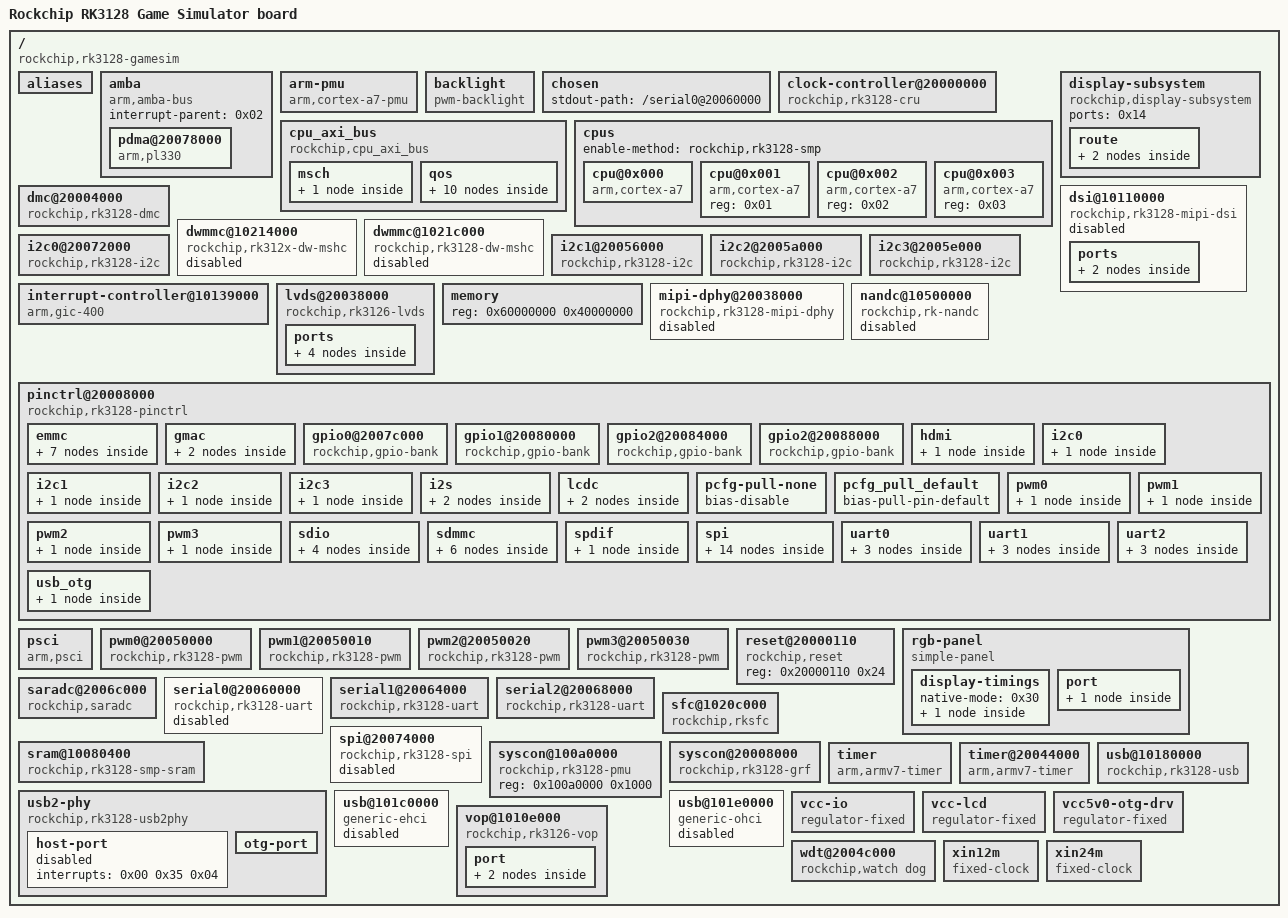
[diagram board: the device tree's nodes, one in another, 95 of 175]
/dts-v1/;

/ {
	#address-cells = <0x01>;
	#size-cells = <0x01>;
	compatible = "rockchip,rk3128-gamesim\0rockchip,rk3128";
	interrupt-parent = <0x02>;
	model = "Rockchip RK3128 Game Simulator board";
	rockchip,sram = <0x01>;

	aliases {
		gpio0 = "/pinctrl@20008000/gpio0@2007c000";
		gpio1 = "/pinctrl@20008000/gpio1@20080000";
		gpio2 = "/pinctrl@20008000/gpio2@20084000";
		gpio3 = "/pinctrl@20008000/gpio2@20088000";
		i2c0 = "/i2c0@20072000";
		i2c1 = "/i2c1@20056000";
		i2c2 = "/i2c2@2005a000";
		i2c3 = "/i2c3@2005e000";
		mmc0 = "/dwmmc@1021c000";
		mmc1 = "/dwmmc@10214000";
		serial0 = "/serial0@20060000";
		serial1 = "/serial1@20064000";
		serial2 = "/serial2@20068000";
		spi0 = "/spi@20074000";
	};

	amba {
		#address-cells = <0x01>;
		#size-cells = <0x01>;
		compatible = "arm,amba-bus";
		interrupt-parent = <0x02>;
		ranges;

		pdma@20078000 {
			#dma-cells = <0x01>;
			arm,pl330-broken-no-flushp;
			clock-names = "apb_pclk";
			clocks = <0x03 0xc2>;
			compatible = "arm,pl330\0arm,primecell";
			interrupts = <0x00 0x00 0x04 0x00 0x01 0x04>;
			phandle = <0x09>;
			reg = <0x20078000 0x4000>;
		};
	};

	arm-pmu {
		compatible = "arm,cortex-a7-pmu";
		interrupts = <0x00 0x4c 0x04 0x00 0x4d 0x04 0x00 0x4e 0x04 0x00 0x4f 0x04>;
	};

	backlight {
		brightness-levels = <0x00 0x01 0x02 0x03 0x04 0x05 0x06 0x07 0x08 0x09 0x0a 0x0b 0x0c 0x0d 0x0e 0x0f 0x10 0x11 0x12 0x13 0x14 0x15 0x16 0x17 0x18 0x19 0x1a 0x1b 0x1c 0x1d 0x1e 0x1f 0x20 0x21 0x22 0x23 0x24 0x25 0x26 0x27 0x28 0x29 0x2a 0x2b 0x2c 0x2d 0x2e 0x2f 0x30 0x31 0x32 0x33 0x34 0x35 0x36 0x37 0x38 0x39 0x3a 0x3b 0x3c 0x3d 0x3e 0x3f 0x40 0x41 0x42 0x43 0x44 0x45 0x46 0x47 0x48 0x49 0x4a 0x4b 0x4c 0x4d 0x4e 0x4f 0x50 0x51 0x52 0x53 0x54 0x55 0x56 0x57 0x58 0x59 0x5a 0x5b 0x5c 0x5d 0x5e 0x5f 0x60 0x61 0x62 0x63 0x64 0x65 0x66 0x67 0x68 0x69 0x6a 0x6b 0x6c 0x6d 0x6e 0x6f 0x70 0x71 0x72 0x73 0x74 0x75 0x76 0x77 0x78 0x79 0x7a 0x7b 0x7c 0x7d 0x7e 0x7f 0x80 0x81 0x82 0x83 0x84 0x85 0x86 0x87 0x88 0x89 0x8a 0x8b 0x8c 0x8d 0x8e 0x8f 0x90 0x91 0x92 0x93 0x94 0x95 0x96 0x97 0x98 0x99 0x9a 0x9b 0x9c 0x9d 0x9e 0x9f 0xa0 0xa1 0xa2 0xa3 0xa4 0xa5 0xa6 0xa7 0xa8 0xa9 0xaa 0xab 0xac 0xad 0xae 0xaf 0xb0 0xb1 0xb2 0xb3 0xb4 0xb5 0xb6 0xb7 0xb8 0xb9 0xba 0xbb 0xbc 0xbd 0xbe 0xbf 0xc0 0xc1 0xc2 0xc3 0xc4 0xc5 0xc6 0xc7 0xc8 0xc9 0xca 0xcb 0xcc 0xcd 0xce 0xcf 0xd0 0xd1 0xd2 0xd3 0xd4 0xd5 0xd6 0xd7 0xd8 0xd9 0xda 0xdb 0xdc 0xdd 0xde 0xdf 0xe0 0xe1 0xe2 0xe3 0xe4 0xe5 0xe6 0xe7 0xe8 0xe9 0xea 0xeb 0xec 0xed 0xee 0xef 0xf0 0xf1 0xf2 0xf3 0xf4 0xf5 0xf6 0xf7 0xf8 0xf9 0xfa 0xfb 0xfc 0xfd 0xfe 0xff>;
		compatible = "pwm-backlight";
		default-brightness-level = <0xff>;
		phandle = <0x2d>;
		pwms = <0x2b 0x00 0x61a8 0x00>;
		status = "okay";
	};

	chosen {
		stdout-path = "/serial0@20060000";
	};

	clock-controller@20000000 {
		#clock-cells = <0x01>;
		#reset-cells = <0x01>;
		assigned-clock-rates = <0x2367b880>;
		assigned-clocks = <0x03 0x04>;
		compatible = "rockchip,rk3128-cru";
		phandle = <0x03>;
		reg = <0x20000000 0x1000>;
		rockchip,grf = <0x05>;
		u-boot,dm-pre-reloc;
	};

	cpu_axi_bus {
		#address-cells = <0x01>;
		#size-cells = <0x01>;
		compatible = "rockchip,cpu_axi_bus";
		ranges;

		msch {
			#address-cells = <0x01>;
			#size-cells = <0x01>;
			ranges;

			msch@10128000 {
				reg = <0x10128000 0x20>;
				rockchip,read-latency = <0x3f>;
			};
		};

		qos {
			#address-cells = <0x01>;
			#size-cells = <0x01>;
			ranges;

			core {
				reg = <0x1012a000 0x20>;
			};

			crypto {
				reg = <0x10128080 0x20>;
			};

			ebc {
				reg = <0x1012f080 0x20>;
			};

			gpu {
				reg = <0x1012d000 0x20>;
			};

			iep {
				reg = <0x1012f100 0x20>;
			};

			lcdc {
				reg = <0x1012f180 0x20>;
				rockchip,priority = <0x03 0x03>;
			};

			peri {
				reg = <0x1012c000 0x20>;
			};

			rga {
				reg = <0x1012f000 0x20>;
			};

			vip {
				reg = <0x1012f200 0x20>;
				rockchip,priority = <0x03 0x03>;
			};

			vpu {
				reg = <0x1012e000 0x20>;
			};
		};
	};

	cpus {
		#address-cells = <0x01>;
		#size-cells = <0x00>;
		enable-method = "rockchip,rk3128-smp";

		cpu@0x000 {
			#cooling-cells = <0x02>;
			clock-latency = <0x9c40>;
			clocks = <0x03 0x05>;
			compatible = "arm,cortex-a7";
			device_type = "cpu";
			operating-points = <0xc7380 0xf4240>;
			reg = <0x00>;
		};

		cpu@0x001 {
			compatible = "arm,cortex-a7";
			device_type = "cpu";
			reg = <0x01>;
		};

		cpu@0x002 {
			compatible = "arm,cortex-a7";
			device_type = "cpu";
			reg = <0x02>;
		};

		cpu@0x003 {
			compatible = "arm,cortex-a7";
			device_type = "cpu";
			reg = <0x03>;
		};
	};

	display-subsystem {
		compatible = "rockchip,display-subsystem";
		ports = <0x14>;
		status = "okay";

		route {

			route-dsi {
				charge_logo,mode = "center";
				connect = <0x13>;
				logo,kernel = "logo_kernel.bmp";
				logo,mode = "fullscreen";
				logo,uboot = "logo.bmp";
				status = "disabled";
			};

			route-lvds {
				charge_logo,mode = "center";
				connect = <0x15>;
				logo,kernel = "logo_kernel.bmp";
				logo,mode = "fullscreen";
				logo,uboot = "logo.bmp";
				status = "okay";
			};
		};
	};

	dmc@20004000 {
		compatible = "rockchip,rk3128-dmc\0syscon";
		reg = <0x00 0x20004000 0x00 0x1000>;
		u-boot,dm-pre-reloc;
	};

	dsi@10110000 {
		#address-cells = <0x01>;
		#size-cells = <0x00>;
		clock-names = "pclk\0h2p\0hs_clk";
		clocks = <0x03 0x145 0x03 0x1d5 0x12>;
		compatible = "rockchip,rk3128-mipi-dsi";
		interrupts = <0x00 0x21 0x04>;
		phy-names = "mipi_dphy";
		phys = <0x12>;
		reg = <0x10110000 0x4000>;
		reset-names = "apb";
		resets = <0x03 0x89>;
		rockchip,grf = <0x05>;
		status = "disabled";

		ports {

			port {

				endpoint {
					phandle = <0x11>;
					remote-endpoint = <0x13>;
				};
			};
		};
	};

	dwmmc@10214000 {
		bus-width = <0x04>;
		clock-names = "biu\0ciu\0ciu-drv\0ciu-sample";
		clocks = <0x03 0x1c8 0x03 0x44 0x03 0x72 0x03 0x76>;
		compatible = "rockchip,rk312x-dw-mshc\0rockchip,rk3288-dw-mshc";
		fifo-depth = <0x100>;
		interrupts = <0x00 0x0e 0x04>;
		max-frequency = <0x8f0d180>;
		pinctrl-0 = <0x18 0x19 0x1a>;
		pinctrl-names = "default";
		reg = <0x10214000 0x4000>;
		status = "disabled";
	};

	dwmmc@1021c000 {
		bus-width = <0x08>;
		clock-names = "biu\0ciu\0ciu-drv\0ciu-sample";
		clocks = <0x03 0x1cb 0x03 0x47 0x03 0x75 0x03 0x79>;
		compatible = "rockchip,rk3128-dw-mshc\0rockchip,rk3288-dw-mshc";
		default-sample-phase = <0x9e>;
		fifo-depth = <0x100>;
		interrupts = <0x00 0x10 0x04>;
		max-frequency = <0x8f0d180>;
		num-slots = <0x01>;
		pinctrl-0 = <0x1b 0x1c 0x1d>;
		pinctrl-names = "default";
		reg = <0x1021c000 0x4000>;
		reset-names = "reset";
		resets = <0x03 0x53>;
		status = "disabled";
		u-boot,dm-pre-reloc;
	};

	i2c0@20072000 {
		#address-cells = <0x01>;
		#size-cells = <0x00>;
		clock-names = "i2c";
		clocks = <0x03 0x14c>;
		compatible = "rockchip,rk3128-i2c\0rockchip,rk3288-i2c";
		interrupts = <0x00 0x18 0x04>;
		pinctrl-0 = <0x20>;
		pinctrl-names = "default";
		reg = <0x20072000 0x1000>;
	};

	i2c1@20056000 {
		#address-cells = <0x01>;
		#size-cells = <0x00>;
		clock-names = "i2c";
		clocks = <0x03 0x14d>;
		compatible = "rockchip,rk3128-i2c\0rockchip,rk3288-i2c";
		interrupts = <0x00 0x19 0x04>;
		pinctrl-0 = <0x21>;
		pinctrl-names = "default";
		reg = <0x20056000 0x1000>;
	};

	i2c2@2005a000 {
		#address-cells = <0x01>;
		#size-cells = <0x00>;
		clock-names = "i2c";
		clocks = <0x03 0x14e>;
		compatible = "rockchip,rk3128-i2c\0rockchip,rk3288-i2c";
		interrupts = <0x00 0x1a 0x04>;
		pinctrl-0 = <0x22>;
		pinctrl-names = "default";
		reg = <0x2005a000 0x1000>;
	};

	i2c3@2005e000 {
		#address-cells = <0x01>;
		#size-cells = <0x00>;
		clock-names = "i2c";
		clocks = <0x03 0x14f>;
		compatible = "rockchip,rk3128-i2c\0rockchip,rk3288-i2c";
		interrupts = <0x00 0x1b 0x04>;
		pinctrl-0 = <0x23>;
		pinctrl-names = "default";
		reg = <0x2005e000 0x1000>;
	};

	interrupt-controller@10139000 {
		#address-cells = <0x00>;
		#interrupt-cells = <0x03>;
		compatible = "arm,gic-400";
		interrupt-controller;
		interrupts = <0x01 0x09 0xf04>;
		phandle = <0x02>;
		reg = <0x10139000 0x1000 0x1013a000 0x1000 0x1013c000 0x2000 0x1013e000 0x2000>;
	};

	lvds@20038000 {
		compatible = "rockchip,rk3126-lvds";
		pinctrl-0 = <0x1e>;
		pinctrl-names = "default";
		reg = <0x20038000 0x4000 0x10110000 0x100>;
		reg-names = "mipi_lvds_phy\0mipi_lvds_ctl";
		rockchip,grf = <0x05>;
		status = "okay";

		ports {
			#address-cells = <0x01>;
			#size-cells = <0x00>;

			port@0 {
				reg = <0x00>;

				endpoint {
					phandle = <0x10>;
					remote-endpoint = <0x15>;
				};
			};

			port@1 {
				reg = <0x01>;

				endpoint {
					phandle = <0x31>;
					remote-endpoint = <0x1f>;
				};
			};
		};
	};

	memory {
		device_type = "memory";
		reg = <0x60000000 0x40000000>;
	};

	mipi-dphy@20038000 {
		#clock-cells = <0x00>;
		#phy-cells = <0x00>;
		clock-names = "ref\0pclk\0h2p";
		clock-output-names = "mipi_dphy_pll";
		clocks = <0x03 0x94 0x03 0x172 0x03 0x1d5>;
		compatible = "rockchip,rk3128-mipi-dphy";
		phandle = <0x12>;
		reg = <0x20038000 0x4000>;
		reset-names = "apb";
		resets = <0x03 0x24>;
		status = "disabled";
	};

	nandc@10500000 {
		clock-names = "clk_nandc\0hclk_nandc";
		clocks = <0x03 0x43 0x03 0x1c5>;
		compatible = "rockchip,rk-nandc";
		interrupts = <0x00 0x12 0x04>;
		nandc_id = <0x00>;
		reg = <0x10500000 0x4000>;
		status = "disabled";
		u-boot,dm-pre-reloc;
	};

	pinctrl@20008000 {
		#address-cells = <0x01>;
		#size-cells = <0x01>;
		compatible = "rockchip,rk3128-pinctrl";
		ranges;
		reg = <0x20008000 0xa8 0x200080a8 0x4c 0x20008118 0x20 0x20008100 0x04>;
		reg-names = "base\0mux\0pull\0drv";
		rockchip,grf = <0x05>;

		emmc {

			emmc-bus1 {
				rockchip,pins = <0x01 0x18 0x02 0x2a>;
			};

			emmc-bus4 {
				rockchip,pins = <0x01 0x18 0x02 0x2a 0x01 0x19 0x02 0x2a 0x01 0x1a 0x02 0x2a 0x01 0x1b 0x02 0x2a>;
			};

			emmc-bus8 {
				phandle = <0x1d>;
				rockchip,pins = <0x01 0x18 0x02 0x2a 0x01 0x19 0x02 0x2a 0x01 0x1a 0x02 0x2a 0x01 0x1b 0x02 0x2a 0x01 0x1c 0x02 0x2a 0x01 0x1d 0x02 0x2a 0x01 0x1e 0x02 0x2a 0x01 0x1f 0x02 0x2a>;
			};

			emmc-clk {
				phandle = <0x1b>;
				rockchip,pins = <0x02 0x07 0x02 0x29>;
			};

			emmc-cmd {
				phandle = <0x1c>;
				rockchip,pins = <0x01 0x16 0x02 0x2a>;
			};

			emmc-cmd1 {
				rockchip,pins = <0x02 0x04 0x02 0x2a>;
			};

			emmc-pwr {
				rockchip,pins = <0x02 0x05 0x02 0x2a>;
			};
		};

		gmac {

			rgmii-pins {
				rockchip,pins = <0x02 0x08 0x03 0x2a 0x02 0x09 0x03 0x2a 0x02 0x0b 0x03 0x2a 0x02 0x0c 0x03 0x2a 0x02 0x0d 0x03 0x2a 0x02 0x0e 0x03 0x2a 0x02 0x10 0x03 0x2a 0x02 0x11 0x03 0x2a 0x02 0x12 0x03 0x2a 0x02 0x13 0x03 0x2a 0x02 0x19 0x03 0x2a 0x02 0x14 0x04 0x2a 0x02 0x15 0x04 0x2a 0x02 0x16 0x04 0x2a 0x02 0x17 0x04 0x2a>;
			};

			rmii-pins {
				rockchip,pins = <0x02 0x08 0x03 0x2a 0x02 0x0c 0x03 0x2a 0x02 0x0d 0x03 0x2a 0x02 0x0e 0x03 0x2a 0x02 0x0f 0x03 0x2a 0x02 0x10 0x03 0x2a 0x02 0x11 0x03 0x2a 0x02 0x13 0x03 0x2a 0x02 0x14 0x03 0x2a 0x02 0x19 0x03 0x2a>;
			};
		};

		gpio0@2007c000 {
			#gpio-cells = <0x02>;
			#interrupt-cells = <0x02>;
			clocks = <0x03 0x140>;
			compatible = "rockchip,gpio-bank";
			gpio-controller;
			interrupt-controller;
			interrupts = <0x00 0x24 0x04>;
			phandle = <0x2f>;
			reg = <0x2007c000 0x100>;
		};

		gpio1@20080000 {
			#gpio-cells = <0x02>;
			#interrupt-cells = <0x02>;
			clocks = <0x03 0x141>;
			compatible = "rockchip,gpio-bank";
			gpio-controller;
			interrupt-controller;
			interrupts = <0x00 0x25 0x04>;
			phandle = <0x32>;
			reg = <0x20080000 0x100>;
		};

		gpio2@20084000 {
			#gpio-cells = <0x02>;
			#interrupt-cells = <0x02>;
			clocks = <0x03 0x142>;
			compatible = "rockchip,gpio-bank";
			gpio-controller;
			interrupt-controller;
			interrupts = <0x00 0x26 0x04>;
			reg = <0x20084000 0x100>;
		};

		gpio2@20088000 {
			#gpio-cells = <0x02>;
			#interrupt-cells = <0x02>;
			clocks = <0x03 0x143>;
			compatible = "rockchip,gpio-bank";
			gpio-controller;
			interrupt-controller;
			interrupts = <0x00 0x27 0x04>;
			reg = <0x20088000 0x100>;
		};

		hdmi {

			hdmii2c-xfer {
				rockchip,pins = <0x00 0x06 0x02 0x29 0x00 0x07 0x02 0x29>;
			};
		};

		i2c0 {

			i2c0-xfer {
				phandle = <0x20>;
				rockchip,pins = <0x00 0x00 0x01 0x29 0x00 0x01 0x01 0x29>;
			};
		};

		i2c1 {

			i2c1-xfer {
				phandle = <0x21>;
				rockchip,pins = <0x00 0x02 0x01 0x29 0x00 0x03 0x01 0x29>;
			};
		};

		i2c2 {

			i2c2-xfer {
				phandle = <0x22>;
				rockchip,pins = <0x02 0x14 0x03 0x29 0x02 0x15 0x03 0x29>;
			};
		};

		i2c3 {

			i2c3-xfer {
				phandle = <0x23>;
				rockchip,pins = <0x00 0x06 0x01 0x29 0x00 0x07 0x01 0x29>;
			};
		};

		i2s {

			i2s-bus {
				rockchip,pins = <0x00 0x08 0x01 0x29 0x00 0x09 0x01 0x29 0x00 0x0b 0x01 0x29 0x00 0x0c 0x01 0x29 0x00 0x0d 0x01 0x29 0x00 0x0e 0x01 0x29>;
			};

			i2s1-bus {
				rockchip,pins = <0x01 0x00 0x01 0x29 0x01 0x01 0x01 0x29 0x01 0x02 0x01 0x29 0x01 0x03 0x01 0x29 0x01 0x04 0x01 0x29 0x01 0x05 0x01 0x29>;
			};
		};

		lcdc {

			lcd-reset {
				phandle = <0x2e>;
				rockchip,pins = <0x00 0x18 0x00 0x29>;
			};

			lcdc-lcdc {
				phandle = <0x1e>;
				rockchip,pins = <0x02 0x08 0x01 0x29 0x02 0x09 0x01 0x29 0x02 0x0a 0x01 0x29 0x02 0x0b 0x01 0x29 0x02 0x0c 0x01 0x29 0x02 0x0d 0x01 0x29 0x02 0x0e 0x01 0x29 0x02 0x0f 0x01 0x29 0x02 0x10 0x01 0x29 0x02 0x11 0x01 0x29 0x02 0x12 0x01 0x29 0x02 0x13 0x01 0x29 0x02 0x14 0x01 0x29 0x02 0x15 0x01 0x29 0x02 0x16 0x01 0x29 0x02 0x17 0x01 0x29 0x02 0x18 0x01 0x29 0x02 0x19 0x01 0x29>;
			};
		};

		pcfg-pull-none {
			bias-disable;
			phandle = <0x29>;
		};

		pcfg_pull_default {
			bias-pull-pin-default;
			phandle = <0x2a>;
		};

		pwm0 {

			pwm0-pin {
				phandle = <0x0c>;
				rockchip,pins = <0x00 0x1a 0x01 0x29>;
			};
		};

		pwm1 {

			pwm1-pin {
				phandle = <0x0d>;
				rockchip,pins = <0x00 0x1b 0x01 0x29>;
			};
		};

		pwm2 {

			pwm2-pin {
				phandle = <0x0e>;
				rockchip,pins = <0x01 0x1c 0x01 0x29>;
			};
		};

		pwm3 {

			pwm3-pin {
				phandle = <0x0f>;
				rockchip,pins = <0x03 0x1a 0x01 0x29>;
			};
		};

		sdio {

			sdio-bus4 {
				rockchip,pins = <0x01 0x01 0x02 0x2a 0x01 0x02 0x02 0x2a 0x01 0x04 0x02 0x2a 0x01 0x05 0x02 0x2a>;
			};

			sdio-clk {
				rockchip,pins = <0x01 0x00 0x02 0x29>;
			};

			sdio-cmd {
				rockchip,pins = <0x00 0x03 0x02 0x2a>;
			};

			sdio-pwren {
				rockchip,pins = <0x00 0x1e 0x01 0x2a>;
			};
		};

		sdmmc {

			sdmmc-bus4 {
				phandle = <0x1a>;
				rockchip,pins = <0x01 0x12 0x01 0x2a 0x01 0x13 0x01 0x2a 0x01 0x14 0x01 0x2a 0x01 0x15 0x01 0x2a>;
			};

			sdmmc-cd {
				rockchip,pins = <0x01 0x11 0x01 0x2a>;
			};

			sdmmc-clk {
				phandle = <0x18>;
				rockchip,pins = <0x01 0x10 0x01 0x29>;
			};

			sdmmc-cmd {
				phandle = <0x19>;
				rockchip,pins = <0x01 0x0f 0x01 0x2a>;
			};

			sdmmc-pwren {
				rockchip,pins = <0x01 0x0e 0x01 0x2a>;
			};

			sdmmc-wp {
				rockchip,pins = <0x01 0x07 0x01 0x2a>;
			};
		};

		spdif {

			spdif-tx {
				rockchip,pins = <0x03 0x1b 0x01 0x29>;
			};
		};

		spi {

			spi0-clk {
				phandle = <0x26>;
				rockchip,pins = <0x01 0x08 0x01 0x2a>;
			};

			spi0-cs0 {
				phandle = <0x27>;
				rockchip,pins = <0x01 0x0b 0x01 0x2a>;
			};

			spi0-cs1 {
				phandle = <0x28>;
				rockchip,pins = <0x01 0x0c 0x01 0x2a>;
			};

			spi0-rx {
				phandle = <0x25>;
				rockchip,pins = <0x01 0x0a 0x01 0x2a>;
			};

			spi0-tx {
				phandle = <0x24>;
				rockchip,pins = <0x01 0x09 0x01 0x2a>;
			};

			spi1-clk {
				rockchip,pins = <0x02 0x00 0x02 0x2a>;
			};

			spi1-cs0 {
				rockchip,pins = <0x01 0x1e 0x03 0x2a>;
			};

			spi1-cs1 {
				rockchip,pins = <0x01 0x1f 0x03 0x2a>;
			};

			spi1-rx {
				rockchip,pins = <0x01 0x1c 0x03 0x2a>;
			};

			spi1-tx {
				rockchip,pins = <0x01 0x1d 0x03 0x2a>;
			};

			spi2-clk {
				rockchip,pins = <0x00 0x09 0x02 0x2a>;
			};

			spi2-cs0 {
				rockchip,pins = <0x00 0x0e 0x02 0x2a>;
			};

			spi2-rx {
				rockchip,pins = <0x00 0x0d 0x02 0x2a>;
			};

			spi2-tx {
				rockchip,pins = <0x00 0x0b 0x02 0x2a>;
			};
		};

		uart0 {

			uart0-cts {
				phandle = <0x07>;
				rockchip,pins = <0x02 0x1d 0x02 0x29>;
			};

			uart0-rts {
				phandle = <0x08>;
				rockchip,pins = <0x00 0x11 0x02 0x29>;
			};

			uart0-xfer {
				phandle = <0x06>;
				rockchip,pins = <0x02 0x1a 0x02 0x2a 0x02 0x1b 0x02 0x29>;
			};
		};

		uart1 {

			uart1-cts {
				rockchip,pins = <0x01 0x08 0x02 0x29>;
			};

			uart1-rts {
				rockchip,pins = <0x01 0x0b 0x02 0x29>;
			};

			uart1-xfer {
				phandle = <0x0a>;
				rockchip,pins = <0x01 0x09 0x02 0x2a 0x01 0x0a 0x02 0x2a>;
			};
		};

		uart2 {

			uart2-cts {
				rockchip,pins = <0x00 0x19 0x01 0x29>;
			};

			uart2-rts {
				rockchip,pins = <0x00 0x18 0x01 0x29>;
			};

			uart2-xfer {
				phandle = <0x0b>;
				rockchip,pins = <0x01 0x12 0x02 0x2a 0x01 0x13 0x02 0x29>;
			};
		};

		usb_otg {

			otg-drv {
				rockchip,pins = <0x02 0x0c 0x00 0x29>;
			};
		};
	};

	psci {
		compatible = "arm,psci";
		cpu_off = <0x84000002>;
		cpu_on = <0x84000003>;
		cpu_suspend = <0x84000001>;
		method = "smc";
		migrate = <0x84000005>;
	};

	pwm0@20050000 {
		#pwm-cells = <0x03>;
		clock-names = "pwm";
		clocks = <0x03 0x15e>;
		compatible = "rockchip,rk3128-pwm\0rockchip,rk3288-pwm";
		phandle = <0x2b>;
		pinctrl-0 = <0x0c>;
		pinctrl-names = "active";
		reg = <0x20050000 0x10>;
		status = "okay";
	};

	pwm1@20050010 {
		#pwm-cells = <0x02>;
		clock-names = "pwm";
		clocks = <0x03 0x15e>;
		compatible = "rockchip,rk3128-pwm\0rockchip,rk3288-pwm";
		pinctrl-0 = <0x0d>;
		pinctrl-names = "active";
		reg = <0x20050010 0x10>;
	};

	pwm2@20050020 {
		#pwm-cells = <0x02>;
		clock-names = "pwm";
		clocks = <0x03 0x15e>;
		compatible = "rockchip,rk3128-pwm\0rockchip,rk3288-pwm";
		pinctrl-0 = <0x0e>;
		pinctrl-names = "active";
		reg = <0x20050020 0x10>;
	};

	pwm3@20050030 {
		#pwm-cells = <0x02>;
		clock-names = "pwm";
		clocks = <0x03 0x15e>;
		compatible = "rockchip,rk3128-pwm\0rockchip,rk3288-pwm";
		pinctrl-0 = <0x0f>;
		pinctrl-names = "active";
		reg = <0x20050030 0x10>;
	};

	reset@20000110 {
		#reset-cells = <0x01>;
		compatible = "rockchip,reset";
		reg = <0x20000110 0x24>;
	};

	rgb-panel {
		backlight = <0x2d>;
		bus-format = <0x1009>;
		compatible = "simple-panel";
		enable-delay-ms = <0x82>;
		height-mm = <0x43>;
		pinctrl-0 = <0x2e>;
		pinctrl-names = "default";
		power-supply = <0x2c>;
		prepare-delay-ms = <0x64>;
		reset-delay-ms = <0x3c>;
		reset-gpios = <0x2f 0x18 0x01>;
		rockchip,data-width = <0x12>;
		rockchip,output = "rgb";
		width-mm = <0x69>;

		display-timings {
			native-mode = <0x30>;

			timing0 {
				clock-frequency = <0x6453980>;
				de-active = <0x00>;
				hactive = <0x400>;
				hback-porch = <0xa0>;
				hfront-porch = <0xa0>;
				hsync-active = <0x00>;
				hsync-len = <0x0a>;
				phandle = <0x30>;
				pixelclk-active = <0x01>;
				vactive = <0x258>;
				vback-porch = <0x17>;
				vfront-porch = <0x0c>;
				vsync-active = <0x00>;
				vsync-len = <0x0a>;
			};
		};

		port {

			endpoint {
				phandle = <0x1f>;
				remote-endpoint = <0x31>;
			};
		};
	};

	saradc@2006c000 {
		#io-channel-cells = <0x01>;
		clock-names = "saradc\0apb_pclk";
		clocks = <0x03 0x5b 0x03 0x13e>;
		compatible = "rockchip,saradc";
		interrupts = <0x00 0x11 0x04>;
		reg = <0x2006c000 0x100>;
		reset-names = "saradc-apb";
		resets = <0x03 0x57>;
		status = "okay";
	};

	serial0@20060000 {
		#dma-cells = <0x02>;
		clock-frequency = <0x16e3600>;
		clock-names = "baudclk\0apb_pclk";
		clocks = <0x03 0x4d 0x03 0x155>;
		compatible = "rockchip,rk3128-uart\0snps,dw-apb-uart";
		dmas = <0x09 0x02 0x09 0x03>;
		interrupts = <0x00 0x14 0x04>;
		pinctrl-0 = <0x06 0x07 0x08>;
		pinctrl-names = "default";
		reg = <0x20060000 0x100>;
		reg-io-width = <0x04>;
		reg-shift = <0x02>;
		status = "disabled";
		u-boot,dm-pre-reloc;
	};

	serial1@20064000 {
		#dma-cells = <0x02>;
		clock-frequency = <0x16e3600>;
		clock-names = "baudclk\0apb_pclk";
		clocks = <0x03 0x4e 0x03 0x156>;
		compatible = "rockchip,rk3128-uart\0snps,dw-apb-uart";
		dmas = <0x09 0x04 0x09 0x05>;
		interrupts = <0x00 0x15 0x04>;
		pinctrl-0 = <0x0a>;
		pinctrl-names = "default";
		reg = <0x20064000 0x100>;
		reg-io-width = <0x04>;
		reg-shift = <0x02>;
	};

	serial2@20068000 {
		#dma-cells = <0x02>;
		clock-frequency = <0x16e3600>;
		clock-names = "baudclk\0apb_pclk";
		clocks = <0x03 0x4f 0x03 0x157>;
		compatible = "rockchip,rk3128-uart\0snps,dw-apb-uart";
		dmas = <0x09 0x06 0x09 0x07>;
		interrupts = <0x00 0x16 0x04>;
		pinctrl-0 = <0x0b>;
		pinctrl-names = "default";
		reg = <0x20068000 0x100>;
		reg-io-width = <0x04>;
		reg-shift = <0x02>;
		u-boot,dm-pre-reloc;
	};

	sfc@1020c000 {
		clock-names = "clk_sfc\0hclk_sfc";
		clocks = <0x03 0x99 0x03 0x1b7>;
		compatible = "rockchip,rksfc";
		interrupts = <0x00 0x32 0x04>;
		reg = <0x1020c000 0x8000>;
		status = "okay";
		u-boot,dm-pre-reloc;
	};

	spi@20074000 {
		#address-cells = <0x01>;
		#size-cells = <0x00>;
		clock-names = "spiclk\0apb_pclk";
		compatible = "rockchip,rk3128-spi\0rockchip,rk3288-spi";
		dma-names = "tx\0rx";
		dmas = <0x09 0x08 0x09 0x09>;
		interrupts = <0x00 0x17 0x04>;
		pinctrl-0 = <0x24 0x25 0x26 0x27 0x28>;
		pinctrl-names = "default";
		reg = <0x20074000 0x1000>;
		status = "disabled";
	};

	sram@10080400 {
		compatible = "rockchip,rk3128-smp-sram\0mmio-sram";
		map-cacheable;
		map-exec;
		phandle = <0x01>;
		reg = <0x10080400 0x1c00>;
	};

	syscon@100a0000 {
		#address-cells = <0x01>;
		#size-cells = <0x01>;
		compatible = "rockchip,rk3128-pmu\0syscon\0simple-mfd";
		reg = <0x100a0000 0x1000>;
	};

	syscon@20008000 {
		compatible = "rockchip,rk3128-grf\0syscon";
		phandle = <0x05>;
		reg = <0x20008000 0x1000>;
		u-boot,dm-pre-reloc;
	};

	timer {
		arm,cpu-registers-not-fw-configured;
		clock-frequency = <0x16e3600>;
		compatible = "arm,armv7-timer";
		interrupts = <0x01 0x0d 0xf04 0x01 0x0e 0xf04>;
	};

	timer@20044000 {
		compatible = "arm,armv7-timer";
		interrupts = <0x00 0x1c 0x04>;
		reg = <0x20044000 0xb8>;
		rockchip,broadcast = <0x01>;
	};

	usb2-phy {
		#clock-cells = <0x00>;
		#phy-cells = <0x01>;
		clock-names = "phyclk";
		clock-output-names = "usb480m_phy";
		clocks = <0x03 0x8e>;
		compatible = "rockchip,rk3128-usb2phy";
		phandle = <0x16>;
		reg = <0x17c 0x0c>;
		rockchip,grf = <0x05>;
		status = "okay";

		host-port {
			#phy-cells = <0x00>;
			interrupt-names = "linestate";
			interrupts = <0x00 0x35 0x04>;
			status = "disabled";
		};

		otg-port {
			#phy-cells = <0x00>;
			interrupt-names = "otg-bvalid\0otg-id\0linestate";
			interrupts = <0x00 0x23 0x04 0x00 0x33 0x04 0x00 0x34 0x04>;
			status = "okay";
		};
	};

	usb@10180000 {
		compatible = "rockchip,rk3128-usb\0rockchip,rk3288-usb\0snps,dwc2";
		dr_mode = "otg";
		g-use-dma;
		hnp-srp-disable;
		interrupts = <0x00 0x0a 0x04>;
		phy-names = "usb";
		phys = <0x16 0x00>;
		reg = <0x10180000 0x40000>;
		status = "okay";
		vbus-supply = <0x17>;
	};

	usb@101c0000 {
		compatible = "generic-ehci";
		interrupts = <0x00 0x0b 0x04>;
		phy-names = "usb";
		phys = <0x16 0x01>;
		reg = <0x101c0000 0x20000>;
		status = "disabled";
	};

	usb@101e0000 {
		compatible = "generic-ohci";
		interrupts = <0x00 0x20 0x04>;
		phy-names = "usb";
		phys = <0x16 0x01>;
		reg = <0x101e0000 0x20000>;
		status = "disabled";
	};

	vcc-io {
		compatible = "regulator-fixed";
		phandle = <0x33>;
		regulator-always-on;
		regulator-boot-on;
		regulator-max-microvolt = <0x325aa0>;
		regulator-min-microvolt = <0x325aa0>;
		regulator-name = "vcc_io";
	};

	vcc-lcd {
		compatible = "regulator-fixed";
		gpio = <0x32 0x0c 0x01>;
		phandle = <0x2c>;
		regulator-max-microvolt = <0x325aa0>;
		regulator-min-microvolt = <0x325aa0>;
		regulator-name = "vcc_lcd";
		vin-supply = <0x33>;
	};

	vcc5v0-otg-drv {
		compatible = "regulator-fixed";
		phandle = <0x17>;
		regulator-max-microvolt = <0x4c4b40>;
		regulator-min-microvolt = <0x4c4b40>;
	};

	vop@1010e000 {
		clock-names = "aclk_vop\0dclk_vop\0hclk_vop";
		clocks = <0x03 0xcc 0x03 0xbe 0x03 0x1cf>;
		compatible = "rockchip,rk3126-vop";
		interrupts = <0x00 0x09 0x04>;
		reg = <0x1010e000 0x100 0x1010ec00 0x400>;
		reg-names = "regs\0gamma_lut";
		status = "okay";

		port {
			#address-cells = <0x01>;
			#size-cells = <0x00>;
			phandle = <0x14>;

			endpoint@1 {
				phandle = <0x15>;
				reg = <0x01>;
				remote-endpoint = <0x10>;
			};

			endpoint@2 {
				phandle = <0x13>;
				reg = <0x01>;
				remote-endpoint = <0x11>;
			};
		};
	};

	wdt@2004c000 {
		clock-names = "pclk_wdt";
		compatible = "rockchip,watch dog";
		interrupts = <0x00 0x22 0x04>;
		reg = <0x2004c000 0x100>;
		rockchip,atboot = <0x01>;
		rockchip,debug = <0x00>;
		rockchip,irq = <0x01>;
		rockchip,timeout = <0x3c>;
	};

	xin12m {
		#clock-cells = <0x00>;
		clock-frequency = <0xb71b00>;
		clock-output-names = "xin12m";
		clocks = <0x04>;
		compatible = "fixed-clock";
	};

	xin24m {
		#clock-cells = <0x00>;
		clock-frequency = <0x16e3600>;
		clock-output-names = "xin24m";
		compatible = "fixed-clock";
		phandle = <0x04>;
	};
};
